# MB9AF15xM register map
File version: 1.7
Registers are 32-bit, read-write, reset 0x0 unless marked. A register's access mark holds for its fields unless they carry their own. Offsets are from the block's base; [hi:lo] are bit positions; {n}, {i} and the like mark numbered series.

## RTC — REAL-TIME CLOCK
Base 0x4003B000
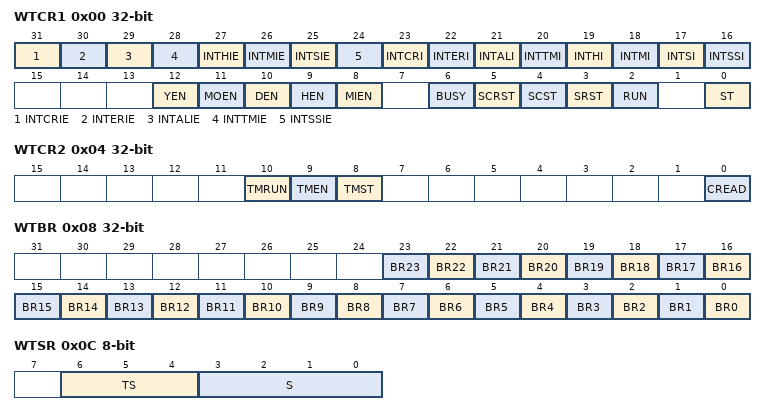
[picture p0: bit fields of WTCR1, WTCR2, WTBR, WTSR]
0x00 WTCR1 — Control Register 1
  [31] INTCRIE — Year/month/date/hour/minute/second/day of the week counter value read completion interrupt enable bit
  [30] INTERIE — Time rewrite error interrupt enable bit
  [29] INTALIE — Alarm interrupt enable bit
  [28] INTTMIE — Timer interrupt enable bit
  [27] INTHIE — 1-hour interrupt enable bit
  [26] INTMIE — 1-minute interrupt enable bit
  [25] INTSIE — 1-second interrupt enable bit
  [24] INTSSIE — 0.5-second interrupt enable bit
  [23] INTCRI — Year/month/date/hour/minute/second/day of the week counter value read completion interrupt flag bit
  [22] INTERI — Time rewrite error interrupt flag bit
  [21] INTALI — Alarm interrupt flag bit
  [20] INTTMI — Timer interrupt flag bit
  [19] INTHI — 1-hour interrupt flag bit
  [18] INTMI — 1-minute interrupt flag bit
  [17] INTSI — 1-second interrupt flag bit
  [16] INTSSI — 0.5-second interrupt flag bit
  [12] YEN — Alarm year register enable bit
  [11] MOEN — Alarm month register enable bit
  [10] DEN — Alarm date register enable bit
  [9] HEN — Alarm hour register enable bit
  [8] MIEN — Alarm minute register enable bit
  [6] BUSY ro — Busy bit
  [5] SCRST — Sub second generation/1-second generation counter reset bit
  [4] SCST — 1-second clock output stop bit
  [3] SRST — RTC reset bit
  [2] RUN ro — RTC count block operation bit
  [0] ST — Start bit
0x04 WTCR2 — Control Register 2
  [10] TMRUN ro — Timer counter operation bit
  [9] TMEN — Timer counter control bit
  [8] TMST — Timer counter start bit
  [0] CREAD — Year/month/date/hour/minute/second/day of the week counter value read control bit
0x08 WTBR — Counter Cycle Setting Register
  [n] BR{n} (n=0..23) — Bit{n} of WTBR
0x0C WTSR 8-bit — Second Register
  [6:4] TS — the second digit of the second
  [3:0] S — the first digit of the second
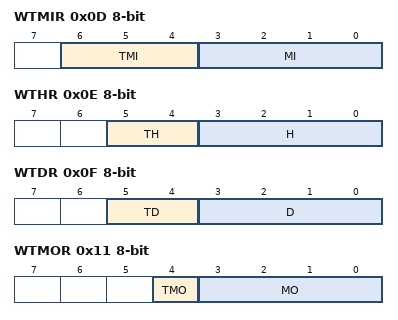
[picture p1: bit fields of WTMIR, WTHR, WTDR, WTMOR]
0x0D WTMIR 8-bit — Minute Register
  [6:4] TMI — the second digit of the minute
  [3:0] MI — the first digit of the minute
0x0E WTHR 8-bit — Hour register
  [5:4] TH — the second digit of the hour
  [3:0] H — the first digit of the hour
0x0F WTDR 8-bit — Date Register
  [5:4] TD — the second digit of the date
  [3:0] D — the first digit of the date
0x10 WTDW 8-bit — Day of the Week Register
  [2:0] DW — Day of the week
0x11 WTMOR 8-bit — Month Register
  [4] TMO — the second digit in the month
  [3:0] MO — the first digit of the month
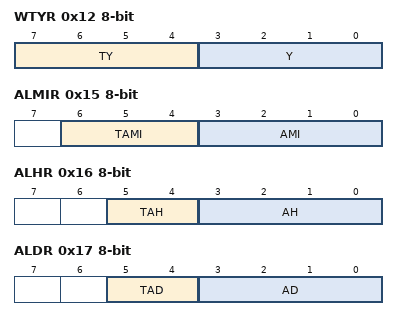
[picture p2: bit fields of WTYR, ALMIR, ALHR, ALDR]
0x12 WTYR 8-bit — Year Register
  [7:4] TY — the second digit of the year
  [3:0] Y — the first digit of the year
0x15 ALMIR 8-bit — Alarm Minute Register
  [6:4] TAMI — the second digit of the alarm-set minute
  [3:0] AMI — the first digit of the alarm-set minute
0x16 ALHR 8-bit — Alarm Hour Register
  [5:4] TAH — the second digit of the alarm-set hour
  [3:0] AH — the first digit of the alarm-set hour
0x17 ALDR 8-bit — Alarm Date Register
  [5:4] TAD — the second digit of the alarm-set date
  [3:0] AD — the first digit of the alarm-set date
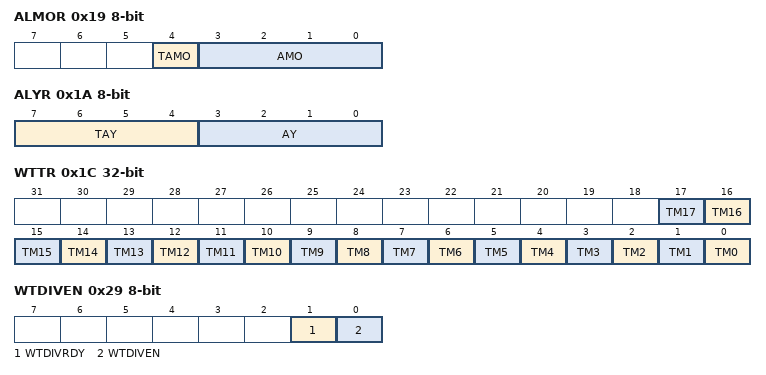
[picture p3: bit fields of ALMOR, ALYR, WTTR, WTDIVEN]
0x19 ALMOR 8-bit — Alarm Month Register
  [4] TAMO — the second digit of the alarm-set month
  [3:0] AMO — the first digit of the alarm-set month
0x1A ALYR 8-bit — Alarm Years Register
  [7:4] TAY — the second digit of the alarm-set year
  [3:0] AY — the first digit of the alarm-set year
0x1C WTTR — Timer Setting Register
  [n] TM{n} (n=0..17) — Bit{n} of WTTR
0x20 WTCLKS 8-bit — Clock Selection Register
  [0] WTCLKS — Input clock selection bit
0x21 WTCLKM 8-bit ro — Selection Clock Status Register
  [1:0] WTCLKM — Clock selection status bit
0x24 WTCAL 16-bit — Frequency Correction Value Setting Register
  [9:0] WTCAL — Frequency correction value
0x26 WTCALEN 8-bit — Frequency Correction Enable Register
  [0] WTCALEN — Frequency correction enable bit
0x28 WTDIV 8-bit — Divider Ratio Setting Register
  [3:0] WTDIV — Divider ratio
0x29 WTDIVEN 8-bit — Divider Output Enable Register
  [1] WTDIVRDY ro — Divider status bit
  [0] WTDIVEN — Divider enable bit
0x2C WTCALPRD 8-bit reset 0x13 — Frequency Correction Cycle Setting Register
  [5:0] WTCALPRD — frequency correction value
0x30 WTCOSEL 8-bit — RTCCO Output Selection Register
  [0] WTCOSEL — RTCCO output selection bit
